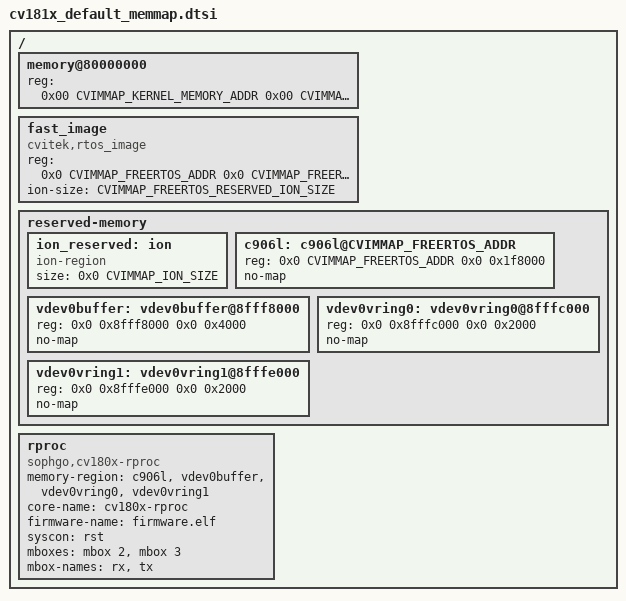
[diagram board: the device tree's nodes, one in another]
/ {
	memory@80000000 {
		device_type = "memory";
		reg = <0x00 CVIMMAP_KERNEL_MEMORY_ADDR 0x00 CVIMMAP_KERNEL_MEMORY_SIZE>;
	};


	fast_image {
		compatible = "cvitek,rtos_image";
		reg-names = "rtos_region";
		reg = <0x0 CVIMMAP_FREERTOS_ADDR 0x0 CVIMMAP_FREERTOS_SIZE>;
		ion-size = <CVIMMAP_FREERTOS_RESERVED_ION_SIZE>;	//reserved ion size for freertos
	};

	reserved-memory {
		#size-cells = <0x2>;
		#address-cells = <0x2>;
		ranges;

		ion_reserved: ion {
			compatible = "ion-region";
			size = <0x0 CVIMMAP_ION_SIZE>;
		};

		// FREERTOS_SIZE = 2 * 1M = 2 * 0x100000 = 0x200000
		// FREERTOS_ADDR = DRAM_BASE + DRAM_SIZE - FREERTOS_SIZE
		//               = 0x80000000 + 256 * 0x100000 - 0x200000
		//               = 0x8FE00000
		c906l: c906l@CVIMMAP_FREERTOS_ADDR {
			reg = <0x0 CVIMMAP_FREERTOS_ADDR 0x0 0x1f8000>;
			no-map;
		};

		// vdev0buffer addr = c906l + 0x1f8000 = 0x8fff8000
		vdev0buffer: vdev0buffer@8fff8000 {
			reg = <0x0 0x8fff8000 0x0 0x4000>;
			no-map;
		};

		// vdev0vring0 addr = vdev0buffer + 0x4000 = 0x8fffc000
		vdev0vring0: vdev0vring0@8fffc000 {
			reg = <0x0 0x8fffc000 0x0 0x2000>;
			no-map;
		};

		// vdev0vring1 addr = vdev0vring0 + 0x2000 = 0x8fffe000 
		vdev0vring1: vdev0vring1@8fffe000 {
			reg = <0x0 0x8fffe000 0x0 0x2000>;
 			no-map;
 		};
	};

	rproc: rproc {
		compatible = "sophgo,cv180x-rproc";
		memory-region = <&c906l>, <&vdev0buffer>, <&vdev0vring0> , <&vdev0vring1>;
		core-name = "cv180x-rproc";
		firmware-name = "firmware.elf";
		syscon = <&rst>;
		status = "okay";
		mboxes = <&mbox 2 &mbox 3>;
		mbox-names = "rx", "tx";
	};

};
